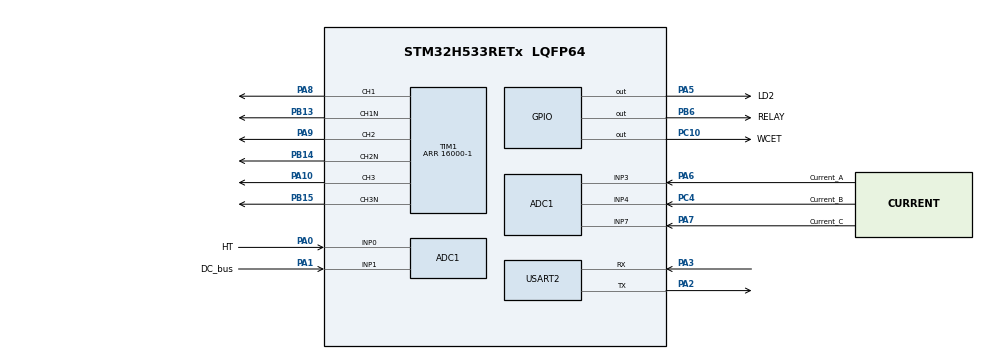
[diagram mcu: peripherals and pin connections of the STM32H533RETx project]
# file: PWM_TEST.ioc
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ADC1.AWD2HighThreshold=0x3FFFFF
ADC1.AWD2ITMode=ENABLE
ADC1.Channel-0\#ChannelRegularConversion=ADC_CHANNEL_0
ADC1.EOCSelection=ADC_EOC_SEQ_CONV
ADC1.EnableAnalogWatchDog1=false
ADC1.EnableAnalogWatchDog2=true
ADC1.EnableInjectedConversion=ENABLE
ADC1.ExternalTrigInjecConv=ADC_EXTERNALTRIGINJEC_T1_TRGO
ADC1.InjAWDChannel-3\#ChannelInjectedConversion=ADC_CHANNEL_3
ADC1.InjAWDChannel-4\#ChannelInjectedConversion=ADC_CHANNEL_4
ADC1.InjAWDChannel-5\#ChannelInjectedConversion=ADC_CHANNEL_7
ADC1.InjMonitoredBy-2\#ChannelInjectedConversion=__NULL
ADC1.InjMonitoredBy-3\#ChannelInjectedConversion=ADC_ANALOGWATCHDOG_2
ADC1.InjMonitoredBy-4\#ChannelInjectedConversion=ADC_ANALOGWATCHDOG_2
ADC1.InjMonitoredBy-5\#ChannelInjectedConversion=ADC_ANALOGWATCHDOG_2
ADC1.InjNumberOfConversion=4
ADC1.InjWDG2ChannelR2=ADC_CHANNEL_3_INJ
ADC1.InjWDG2ChannelR3=ADC_CHANNEL_4_INJ
ADC1.InjWDG2ChannelR4=ADC_CHANNEL_7_INJ
ADC1.InjectedChannel-2\#ChannelInjectedConversion=ADC_CHANNEL_1
ADC1.InjectedChannel-3\#ChannelInjectedConversion=ADC_CHANNEL_3
ADC1.InjectedChannel-4\#ChannelInjectedConversion=ADC_CHANNEL_4
ADC1.InjectedChannel-5\#ChannelInjectedConversion=ADC_CHANNEL_7
ADC1.InjectedConvMode=None
ADC1.InjectedOffsetNumber-2\#ChannelInjectedConversion=ADC_OFFSET_NONE
ADC1.InjectedOffsetNumber-3\#ChannelInjectedConversion=ADC_OFFSET_NONE
ADC1.InjectedOffsetNumber-4\#ChannelInjectedConversion=ADC_OFFSET_NONE
ADC1.InjectedOffsetNumber-5\#ChannelInjectedConversion=ADC_OFFSET_NONE
ADC1.InjectedRank-2\#ChannelInjectedConversion=1
ADC1.InjectedRank-3\#ChannelInjectedConversion=2
ADC1.InjectedRank-4\#ChannelInjectedConversion=3
ADC1.InjectedRank-5\#ChannelInjectedConversion=4
ADC1.InjectedSamplingTime-2\#ChannelInjectedConversion=ADC_SAMPLETIME_47CYCLES_5
ADC1.InjectedSamplingTime-3\#ChannelInjectedConversion=ADC_SAMPLETIME_47CYCLES_5
ADC1.InjectedSamplingTime-4\#ChannelInjectedConversion=ADC_SAMPLETIME_47CYCLES_5
ADC1.InjectedSamplingTime-5\#ChannelInjectedConversion=ADC_SAMPLETIME_47CYCLES_5
ADC1.MonitoredBy-0\#ChannelRegularConversion=__NULL
ADC1.NbrOfConversion=1
ADC1.NbrOfConversionFlag=1
ADC1.OffsetNumber-0\#ChannelRegularConversion=ADC_OFFSET_NONE
ADC1.Overrun=ADC_OVR_DATA_OVERWRITTEN
ADC1.Rank-0\#ChannelRegularConversion=1
ADC1.SamplingTime-0\#ChannelRegularConversion=ADC_SAMPLETIME_640CYCLES_5
ADC1.injectedQueueMode=DISABLE
ADC1.master=1
BOOTPATH.BootPathName=LEGACY
BOOTPATH.UserSelectedBootPath=LEGACY
CORTEX_M33_NS.Number-Cortex_Memory_Protection_Unit_Region0_OTP_RO_AREAS_Settings=MPU_REGION_NUMBER0
CORTEX_M33_NS.default_mode_Activation=1
CORTEX_M33_NS.userName=CORTEX_M33
GPDMA1.CIRCULARMODE_GPDMACH0=DISABLE
GPDMA1.CIRCULARMODE_GPDMACH1=DISABLE
GPDMA1.DESTINC_GPDMACH0=DMA_DINC_FIXED
GPDMA1.DESTINC_GPDMACH1=DMA_DINC_INCREMENTED
GPDMA1.DIRECTION_GPDMACH0=DMA_MEMORY_TO_PERIPH
GPDMA1.IPHANDLE_GPDMACH0-SIMPLEREQUEST_GPDMACH0=__NULL
GPDMA1.IPHANDLE_GPDMACH1-SIMPLEREQUEST_GPDMACH1=__NULL
GPDMA1.REQUEST_GPDMACH0=GPDMA1_REQUEST_USART2_TX
GPDMA1.REQUEST_GPDMACH1=GPDMA1_REQUEST_USART2_RX
GPDMA1.SRCINC_GPDMACH0=DMA_SINC_INCREMENTED
GPDMA1.TRIGGERPOLARITY_GPDMACH0=DMA_TRIG_POLARITY_MASKED
Mcu.Family=STM32H5
Mcu.Name=STM32H533RETx
Mcu.Package=LQFP64
NVIC.ADC1_IRQn=true\:0\:0\:false\:false\:false\:true\:true\:true
NVIC.GPDMA1_Channel0_IRQn=true\:0\:0\:false\:false\:false\:false\:true\:true
NVIC.GPDMA1_Channel1_IRQn=true\:0\:0\:false\:false\:false\:false\:true\:true
NVIC.PriorityGroup=NVIC_PRIORITYGROUP_4
NVIC.TIM1_BRK_IRQn=true\:0\:0\:false\:false\:false\:true\:true\:true
NVIC.TIM1_UP_IRQn=true\:0\:0\:false\:false\:false\:true\:true\:true
NVIC.USART2_IRQn=true\:0\:0\:false\:false\:false\:true\:true\:true
PA0.GPIO_Label=HT
PA0.Signal=ADCx_INP0
PA1.GPIO_Label=DC_bus
PA1.Signal=ADCx_INP1
PA10.Signal=S_TIM1_CH3
PA13(JTMS/SWDIO).GPIO_Label=SWDIO
PA13(JTMS/SWDIO).Mode=Trace_Asynchronous_SW
PA13(JTMS/SWDIO).Signal=DEBUG_JTMS-SWDIO
PA14(JTCK/SWCLK).GPIO_Label=SWCLK
PA14(JTCK/SWCLK).Mode=Trace_Asynchronous_SW
PA14(JTCK/SWCLK).Signal=DEBUG_JTCK-SWCLK
PA2.Mode=Asynchronous
PA2.Signal=USART2_TX
PA3.Mode=Asynchronous
PA3.Signal=USART2_RX
PA5.GPIO_Label=LD2
PA5.Signal=GPIO_Output
PA6.GPIO_Label=Current_A
PA6.Signal=ADCx_INP3
PA7.GPIO_Label=Current_C
PA7.Signal=ADCx_INP7
PA8.Signal=S_TIM1_CH1
PA9.Signal=S_TIM1_CH2
PB13.Mode=PWM Generation1 CH1 CH1N
PB13.Signal=TIM1_CH1N
PB14.Mode=PWM Generation2 CH2 CH2N
PB14.Signal=TIM1_CH2N
PB15.Mode=PWM Generation3 CH3 CH3N
PB15.Signal=TIM1_CH3N
PB3(JTDO/TRACESWO).GPIO_Label=SWO
PB3(JTDO/TRACESWO).Mode=Trace_Asynchronous_SW
PB3(JTDO/TRACESWO).Signal=DEBUG_JTDO-SWO
PB6.GPIO_Label=RELAY
PB6.Signal=GPIO_Output
PC10.GPIO_Label=WCET
PC10.Signal=GPIO_Output
PC4.GPIO_Label=Current_B
PC4.Signal=ADCx_INP4
ProjectManager.HeapSize=0x200
ProjectManager.StackSize=0x1000
ProjectManager.TargetToolchain=CMake
RCC.ADCFreq_Value=32000000
RCC.AHBCLKDivider=RCC_SYSCLK_DIV2
RCC.AHBFreq_Value=32000000
RCC.APB1Freq_Value=32000000
RCC.APB1TimFreq_Value=32000000
RCC.APB2Freq_Value=32000000
RCC.APB2TimFreq_Value=32000000
RCC.APB3Freq_Value=32000000
RCC.CSI_VALUE=4000000
RCC.CortexFreq_Value=32000000
RCC.EPOD_VALUE=4000000
RCC.HCLKFreq_Value=32000000
RCC.HSE_VALUE=25000000
RCC.HSI48_VALUE=48000000
RCC.HSIDiv=RCC_HSI_DIV1
RCC.HSI_VALUE=64000000
RCC.LSE_VALUE=32768
RCC.LSIRC_VALUE=32000
RCC.PLL2FRACN=0
RCC.PLL3FRACN=0
RCC.PLLFRACN=0
RCC.PLLN=32
RCC.SYSCLKFreq_VALUE=64000000
RCC.USBFreq_Value=48000000
RCC.VCOOutputFreq_Value=128000000
SH.ADCx_INP0.0=ADC1_INP0,IN0-Single-Ended
SH.ADCx_INP1.0=ADC1_INP1,IN1-Single-Ended
SH.ADCx_INP3.0=ADC1_INP3,IN3-Single-Ended
SH.ADCx_INP4.0=ADC1_INP4,IN4-Single-Ended
SH.ADCx_INP7.0=ADC1_INP7,IN7-Single-Ended
SH.S_TIM1_CH1.0=TIM1_CH1,PWM Generation1 CH1 CH1N
SH.S_TIM1_CH2.0=TIM1_CH2,PWM Generation2 CH2 CH2N
SH.S_TIM1_CH3.0=TIM1_CH3,PWM Generation3 CH3 CH3N
STMicroelectronics.X-CUBE-ALGOBUILD.1.5.0.LibraryCcDSPOoLibraryJjDSPOoLibrary=true
TIM1.AutoReloadPreload=TIM_AUTORELOAD_PRELOAD_ENABLE
TIM1.AutomaticOutput=TIM_AUTOMATICOUTPUT_DISABLE
TIM1.Break2State=TIM_BREAK2_DISABLE
TIM1.BreakPolarity=TIM_BREAKPOLARITY_LOW
TIM1.BreakState=TIM_BREAK_DISABLE
TIM1.Channel-PWM\ Generation1\ CH1\ CH1N=TIM_CHANNEL_1
TIM1.Channel-PWM\ Generation2\ CH2\ CH2N=TIM_CHANNEL_2
TIM1.Channel-PWM\ Generation3\ CH3\ CH3N=TIM_CHANNEL_3
TIM1.CounterMode=TIM_COUNTERMODE_CENTERALIGNED2
TIM1.DeadTime=255
TIM1.OCNPolarity_1=TIM_OCNPOLARITY_LOW
TIM1.OCNPolarity_2=TIM_OCNPOLARITY_LOW
TIM1.OCNPolarity_3=TIM_OCNPOLARITY_LOW
TIM1.OffStateIDLEMode=TIM_OSSI_ENABLE
TIM1.OffStateRunMode=TIM_OSSR_ENABLE
TIM1.PeriodNoDither=16000-1
TIM1.RepetitionCounter=1
TIM1.TIM_MasterOutputTrigger=TIM_TRGO_UPDATE
USART2.FIFOMode=FIFOMODE_DISABLE
USART2.VirtualMode-Asynchronous=VM_ASYNC
VP_BOOTPATH_VS_BOOTPATH.Mode=BP_Activate
VP_CORTEX_M33_NS_VS_Hclk.Mode=Hclk_Mode
VP_GPDMA1_VS_GPDMACH0.Mode=SIMPLEREQUEST_GPDMACH0
VP_GPDMA1_VS_GPDMACH1.Mode=SIMPLEREQUEST_GPDMACH1
VP_ICACHE_VS_ICACHE.Mode=DirectMappedCache
VP_MEMORYMAP_VS_MEMORYMAP.Mode=CurAppReg
VP_PWR_VS_LPOM.Mode=PowerOptimisation
VP_PWR_VS_SECSignals.Mode=Security/Privilege
VP_STMicroelectronics.X-CUBE-ALGOBUILD_VS_DSPOoLibraryJjLibrary_1.5.0_1.5.0.Mode=DSPOoLibraryJjLibrary
VP_TIM1_VS_ClockSourceINT.Mode=Internal
board=NUCLEO-H533RE

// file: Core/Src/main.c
/* USER CODE BEGIN Header */
/**
  ******************************************************************************
  * @file           : main.c
  * @brief          : Main program body
  ******************************************************************************
  * @attention
  *
  * Copyright (c) 2026 STMicroelectronics.
  * All rights reserved.
  *
  * This software is licensed under terms that can be found in the LICENSE file
  * in the root directory of this software component.
  * If no LICENSE file comes with this software, it is provided AS-IS.
  *
  ******************************************************************************
  */
/* USER CODE END Header */
#include "main.h"
#include "adc.h"
#include "gpdma.h"
#include "icache.h"
#include "tim.h"
#include "usart.h"
#include "gpio.h"

/* USER CODE BEGIN Includes */
#include <arm_math.h>
#include "Logger.h"
#include <stdint.h>
#include "SysTickWrapper.h"
#include "qkernel.h"
#include "MainSM.h"
/* USER CODE END Includes */

void SystemClock_Config(void);
static void MPU_Config(void);

/* USER CODE BEGIN 0 */
GPIO_TypeDef fake_gpio_instance;
/* USER CODE END 0 */

int main(void)
{

  /* MCU Configuration--------------------------------------------------------*/

  /* Reset of all peripherals, Initializes the Flash interface and the Systick. */

  /* MPU Configuration--------------------------------------------------------*/
  MPU_Config();

  /* System interrupt init*/
  NVIC_SetPriorityGrouping(NVIC_PRIORITYGROUP_4);

  /* SysTick_IRQn interrupt configuration */
  NVIC_SetPriority(SysTick_IRQn, NVIC_EncodePriority(NVIC_GetPriorityGrouping(),15, 0));

  /* Configure the system clock */
  SystemClock_Config();

  /* Initialize all configured peripherals */
  MX_GPIO_Init();
  MX_GPDMA1_Init();
  MX_ICACHE_Init();
  MX_TIM1_Init();
  MX_ADC1_Init();
  MX_USART2_UART_Init();
  /* USER CODE BEGIN 2 */
  SysTick_Init();

  qOS_Setup(getSysTick, NULL);
  Enter_MainStateMachine();
  /* USER CODE END 2 */

  /* Infinite loop */
  /* USER CODE BEGIN WHILE */
  while (1)
  {
    // if(GenerateVoltage_IsTaskReady())
    // {
    //   GenerateVoltage_Task();
    // }
    qOS_Run();

    /* USER CODE END WHILE */

  }
}

void SystemClock_Config(void)
{
  LL_FLASH_SetLatency(LL_FLASH_LATENCY_3);
  while(LL_FLASH_GetLatency()!= LL_FLASH_LATENCY_3)
  {
  }

  LL_PWR_SetRegulVoltageScaling(LL_PWR_REGU_VOLTAGE_SCALE3);
  while (LL_PWR_IsActiveFlag_VOS() == 0)
  {
  }
  LL_RCC_HSI_Enable();

   /* Wait till HSI is ready */
  while(LL_RCC_HSI_IsReady() != 1)
  {
  }

  LL_RCC_HSI_SetCalibTrimming(64);
  LL_RCC_HSI_SetDivider(LL_RCC_HSI_DIV_1);
  LL_RCC_SetSysClkSource(LL_RCC_SYS_CLKSOURCE_HSI);

   /* Wait till System clock is ready */
  while(LL_RCC_GetSysClkSource() != LL_RCC_SYS_CLKSOURCE_STATUS_HSI)
  {
  }

  LL_RCC_SetAHBPrescaler(LL_RCC_SYSCLK_DIV_2);
  LL_RCC_SetAPB1Prescaler(LL_RCC_APB1_DIV_1);
  LL_RCC_SetAPB2Prescaler(LL_RCC_APB2_DIV_1);
  LL_RCC_SetAPB3Prescaler(LL_RCC_APB3_DIV_1);

  LL_Init1msTick(32000000);

  LL_SetSystemCoreClock(32000000);
}

 /* MPU Configuration */

void MPU_Config(void)
{

  /* Disables the MPU */
  LL_MPU_Disable();

  /** Initializes and configures the Region 0 and the memory to be protected
  */
  LL_MPU_ConfigRegion(LL_MPU_REGION_NUMBER0, LL_MPU_REGION_ALL_RO|LL_MPU_INSTRUCTION_ACCESS_DISABLE|LL_MPU_ACCESS_NOT_SHAREABLE, LL_MPU_ATTRIBUTES_NUMBER0, 0x08FFF000, 0x08FFFFFF);
  LL_MPU_EnableRegion(LL_MPU_REGION_NUMBER0);

  /** Initializes and configures the Attribute 0 and the memory to be protected
  */
  LL_MPU_ConfigAttributes(LL_MPU_ATTRIBUTES_NUMBER0, LL_MPU_NOT_CACHEABLE);
  /* Enables the MPU */
  LL_MPU_Enable(LL_MPU_CTRL_PRIVILEGED_DEFAULT);

}

void Error_Handler(void)
{
  __disable_irq();
  while (1)
  {
  }
}
